# AUX_ANAIF register map
Vendor: Texas Instruments
Peripheral module from a debugger description file (folder CC2650).
Registers are 32-bit, access per field, reset 0x0 unless marked. A register's access mark holds for its fields unless they carry their own. Offsets are as the file gives them; lines under a group give offsets from that group; [hi:lo] are bit positions; {n}, {i} and the like mark numbered series; 'fields as' and 'values as' point back to an identical list; <NAME> marks a mode.

## AUX_ANAIF — AUX Analog Peripheral Control Module
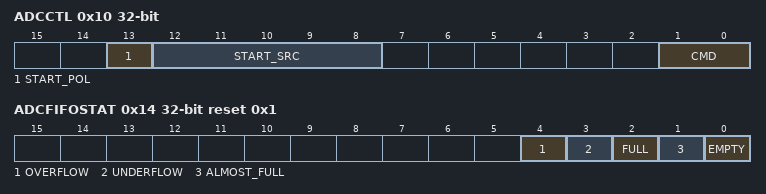
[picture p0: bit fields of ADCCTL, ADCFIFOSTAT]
0x10 ADCCTL — ADC Control
  [13] START_POL rw — Selected active edge for start event / Selected polarity for start event
    1=FALL (Start on falling edge of event); 0=RISE (Start on rising edge of event)
  [12:8] START_SRC rw — Selected source for ADC conversion start event. The start source selected by this field is OR'ed with any trigger coming from writes to ADCTRIG.START. If it is desired to only trigger ADC conversions by writes to ADCTRIG.START one should select NO_EVENT<n> here
    31=ADC_IRQ (Selects ADC_IRQ as start signal); 30=MCU_EV (Selects MCU_EV as start signal); 29=ACLK_REF (Selects ACLK_REF as start signal); {v}=AUXIO{v-13} (Selects AUXIO{v-13} as start signal) (v=13..28); 12=AON_PROG_WU (Selects AON_PROG_WU as start signal); 11=AON_SW (Selects AON_SW as start signal); 10=NO_EVENT1 (No event selected); 9=NO_EVENT0 (No event selected); 6=SMPH_AUTOTAKE_DONE (Selects SMPH_AUTOTAKE_DONE as start signal); 5=TIMER1_EV (Selects TIMER1_EV as start signal); 4=TIMER0_EV (Selects TIMER0_EV as start signal); 3=TDC_DONE (Selects TDC_DONE as start signal); 2=AUX_COMPB (Selects AUX_COMPB as start signal); 1=AUX_COMPA (Selects AUX_COMPA as start signal); 0=RTC_CH2_EV (Selects RTC_CH2_EV as start signal)
  [1:0] CMD rw — ADC interface control command
    3=FLUSH (ADC FIFO flush. Note that CMD needs to be set to 'EN' again for FIFO to be functional after a flush. A flush takes two clock periods on the AUX clock to finish.); 1=EN (ADC interface enabled); 0=DIS (ADC interface disabled)
0x14 ADCFIFOSTAT ro reset 0x1 — ADC FIFO Status FIFO can hold up to four ADC samples
  [4] OVERFLOW — FIFO overflow flag. 0: FIFO has not overflowed. 1: FIFO has overflowed, this flag is sticky until FIFO is flushed.
  [3] UNDERFLOW — FIFO underflow flag. 0: FIFO has not underflowed 1: FIFO has underflowed, this flag is sticky until the FIFO is flushed
  [2] FULL — FIFO full flag. 0: FIFO is not full, i.e. there is less than 4 samples in the FIFO. 1: FIFO is full, i.e. there are 4 samples in the FIFO
  [1] ALMOST_FULL — FIFO almost full flag. 0: There is less than 3 samples in the FIFO, or the FIFO is full in which case the FULL flag is asserted 1: There are 3 samples in the FIFO, i.e. there is room for one more sample
  [0] EMPTY — FIFO empty flag. 0: FIFO contains one or more samples 1: FIFO is empty
0x18 ADCFIFO
  [11:0] DATA rw — FIFO is popped when read. Data is pushed into FIFO when written. Writing is intended for debugging/code development purposes
0x1C ADCTRIG — ADC Trigger
  [0] START wo — Writing to this register will trigger an ADC conversion given that ADCCTL.START_SRC is set to NO_EVENT0 or NO_EVENT1. If other setting is used in ADCCTL.START_SRC behavior can be unpredictable
0x20 ISRCCTL reset 0x1 — Current Source Control
  [0] RESET_N rw — Current source control 0: Current source is clamped 1: Current source is active/charging
